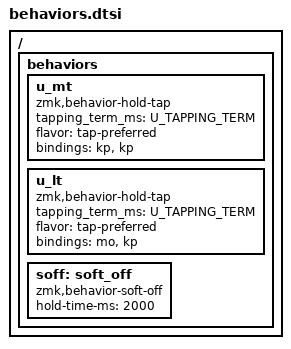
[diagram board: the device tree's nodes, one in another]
MIRYOKU_SHIFT_MACRO(u_bt_sel_0, &bt BT_SEL 0, &bt BT_SEL 0 &bt BT_CLR)
MIRYOKU_SHIFT_MACRO(u_bt_sel_1, &bt BT_SEL 1, &bt BT_SEL 1 &bt BT_CLR)
MIRYOKU_SHIFT_MACRO(u_bt_sel_2, &bt BT_SEL 2, &bt BT_SEL 2 &bt BT_CLR)
MIRYOKU_SHIFT_MACRO(u_bt_sel_3, &bt BT_SEL 3, &bt BT_SEL 3 &bt BT_CLR)
MIRYOKU_SHIFT_MACRO(u_bt_sel_4, &bt BT_SEL 4, &bt BT_SEL 4 &bt BT_CLR)

MIRYOKU_SHIFT_FUNCTION(u_out_tog, &out OUT_BLE, &out OUT_USB)

MIRYOKU_SHIFT_FUNCTION(u_caps_word, &caps_word, &kp CAPS)

MIRYOKU_SHIFT_FUNCTION(u_ep_tog, &ext_power EP_TOG, &ext_power EP_OFF)

MIRYOKU_DOUBLE_TAP_GUARD(u_bootloader, &bootloader)
MIRYOKU_DOUBLE_TAP_GUARD(u_suspend, &suspend)


/ {
  behaviors {
    u_mt: u_mt {
      compatible = "zmk,behavior-hold-tap";
      #binding-cells = <2>;
      tapping_term_ms = <U_TAPPING_TERM>;
      flavor = "tap-preferred";
      bindings = <&kp>, <&kp>;
    };
    u_lt: u_lt {
      compatible = "zmk,behavior-hold-tap";
      #binding-cells = <2>;
      tapping_term_ms = <U_TAPPING_TERM>;
      flavor = "tap-preferred";
      bindings = <&mo>, <&kp>;
    };
    soff: soft_off {
        compatible = "zmk,behavior-soft-off";
        #binding-cells = <0>;
        // split-peripheral-off-on-press;
        hold-time-ms = <2000>; // Only turn off it the key is held for 2 seconds or longer.
    };
  };
};
